# CC430F5123 register map
Registers are 16-bit, read-write, reset 0x0 unless marked. A register's access mark holds for its fields unless they carry their own. Offsets are from the block's base; lines under a group give offsets from that group; [hi:lo] are bit positions; {n}, {i} and the like mark numbered series; 'fields as' and 'values as' point back to an identical list; <NAME> marks a mode.

## Memory map
0x00000000 ADC10_A
0x00000000 AES_Accelerator
0x00000000 Comparator_B
0x00000000 CC1101_Radio_Interface
0x00000000 CRC16
0x00000000 DMA
0x00000000 Flash
0x00000000 MPY_16_Multiplier_16_Bit_Mode
0x00000000 MPY_32_Multiplier_32_Bit_Mode
0x00000000 Port_A
0x00000000 Port_1_2
0x00000000 Port_B
0x00000000 Port_3_4
0x00000000 Port_C
0x00000000 Port_5
0x00000000 Port_J
0x00000000 Port_Mapping_Control
0x00000000 Port_Mapping_Port_1
0x00000000 Port_Mapping_Port_2
0x00000000 Port_Mapping_Port_3
0x00000000 PMM_Power_Management_System
0x00000000 RC_RAM_Control_Module
0x00000000 Shared_Reference
0x00000000 RTC_D_Real_Time_Clock
0x00000000 SFR_Special_Function_Registers
0x00000000 SYS_System_Module
0x00000000 Timer0_A5
0x00000000 Timer1_A3
0x00000000 UCS_Unified_System_Clock
0x00000000 USCI_A0_UART_Mode
0x00000000 USCI_A0_SPI_Mode
0x00000000 USCI_B0_SPI_Mode
0x00000000 USCI_B0_I2C_Mode
0x00000000 Watchdog_Timer

## ADC10_A
Base 0x00000000
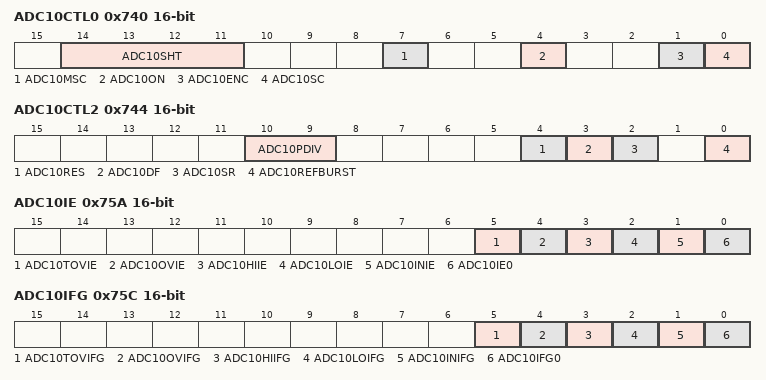
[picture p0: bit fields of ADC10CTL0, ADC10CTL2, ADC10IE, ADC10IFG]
0x740 ADC10CTL0 — ADC10 Control 0
  [14:11] ADC10SHT — ADC10 Sample Hold Select Bit: 0
    {v}=ADC10 Sample Hold Select {v} (v=0..15)
  [7] ADC10MSC — ADC10 Multiple SampleConversion
  [4] ADC10ON — ADC10 On/enable
  [1] ADC10ENC — ADC10 Enable Conversion
  [0] ADC10SC — ADC10 Start Conversion
0x742 ADC10CTL1 — ADC10 Control 1
  [12:11] ADC10SHS — ADC10 Sample/Hold Source 0
    {v}=ADC10 Sample/Hold Source: {v} (v=0..3)
  [9] ADC10SHP — ADC10 Sample/Hold Pulse Mode
  [8] ADC10ISSH — ADC10 Invert Sample Hold Signal
  [9:7] ADC10DIV — ADC10 Clock Divider Select 0
    {v}=ADC10 Clock Divider Select: {v} (v=0..7)
  [5:4] ADC10SSEL — ADC10 Clock Source Select 0
    {v}=ADC10 Clock Source Select: {v} (v=0..3)
  [3:2] ADC10CONSEQ — ADC10 Conversion Sequence Select 0
    {v}=ADC10 Conversion Sequence Select: {v} (v=0..3)
  [0] ADC10BUSY
0x744 ADC10CTL2 — ADC10 Control 2
  [10:9] ADC10PDIV — ADC10 predivider Bit: 0
    0=ADC10 predivider /1; 1=ADC10 predivider /2; 2=ADC10 predivider /64; 3=ADC10 predivider reserved
  [4] ADC10RES — ADC10 Resolution Bit
  [3] ADC10DF — ADC10 Data Format
  [2] ADC10SR — ADC10 Sampling Rate
  [0] ADC10REFBURST — ADC10 Reference Burst
0x746 ADC10LO — ADC10 Window Comparator High Threshold
0x748 ADC10HI — ADC10 Window Comparator High Threshold
0x74A ADC10MCTL0 — ADC10 Memory Control 0
  [8:6] ADC10SREF — ADC10 Select Reference Bit 0
    {v}=ADC10 Select Reference {v} (v=0..7)
  [6:3] ADC10INCH — ADC10 Input Channel Select Bit 0
    {v}=ADC10 Input Channel {v} (v=0..15)
0x752 ADC10MEM0 — ADC10 Conversion Memory 0
0x75A ADC10IE — ADC10 Interrupt Enable
  [5] ADC10TOVIE — ADC10_A conversion-time-overflow Interrupt enable
  [4] ADC10OVIE — ADC10_A ADC10MEM overflow Interrupt enable
  [3] ADC10HIIE — ADC10_A Interrupt enable for upper threshold of the Window comparator
  [2] ADC10LOIE — ADC10_A Interrupt enable for lower threshold of the Window comparator
  [1] ADC10INIE — ADC10_A Interrupt enable for the inside of window of the Window comparator
  [0] ADC10IE0 — ADC10_A Interrupt enable
0x75C ADC10IFG — ADC10 Interrupt Flag
  [5] ADC10TOVIFG — ADC10_A conversion-time-overflow Interrupt Flag
  [4] ADC10OVIFG — ADC10_A ADC10MEM overflow Interrupt Flag
  [3] ADC10HIIFG — ADC10_A Interrupt Flag for upper threshold of the Window comparator
  [2] ADC10LOIFG — ADC10_A Interrupt Flag for lower threshold of the Window comparator
  [1] ADC10INIFG — ADC10_A Interrupt Flag for the inside of window of the Window comparator
  [0] ADC10IFG0 — ADC10_A Interrupt Flag
0x75E ADC10IV — ADC10 Interrupt Vector Word

## AES_Accelerator
Base 0x00000000
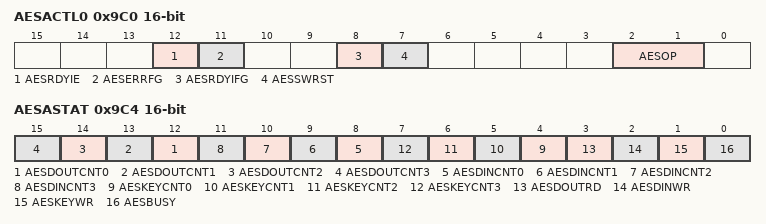
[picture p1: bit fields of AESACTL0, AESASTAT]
0x9C0 AESACTL0 — AES accelerator control register 0
  [12] AESRDYIE — AES ready interrupt enable
  [11] AESERRFG — AES Error Flag
  [8] AESRDYIFG — AES ready interrupt flag
  [7] AESSWRST — AES Software Reset
  [2:1] AESOP — AES Operation Bit: 0
    0=AES Operation: Encrypt; 1=AES Operation: Decrypt (same Key); 2=AES Operation: Generate first round Key; 3=AES Operation: Decrypt (first round Key)
0x9C4 AESASTAT — AES accelerator status register
  [n+12] AESDOUTCNT{n} (n=0..3) — AES Bytes read via AESADOUT Bit: {n}
  [n+8] AESDINCNT{n} (n=0..3) — AES Bytes written via AESADIN Bit: {n}
  [n+4] AESKEYCNT{n} (n=0..3) — AES Bytes written via AESAKEY Bit: {n}
  [3] AESDOUTRD — AES All 16 bytes read from AESADOUT
  [2] AESDINWR — AES All 16 bytes written to AESADIN
  [1] AESKEYWR — AES All 16 bytes written to AESAKEY
  [0] AESBUSY
0x9C6 AESAKEY — AES accelerator key register
0x9C8 AESADIN — AES accelerator data in register
0x9CA AESADOUT — AES accelerator data out register
